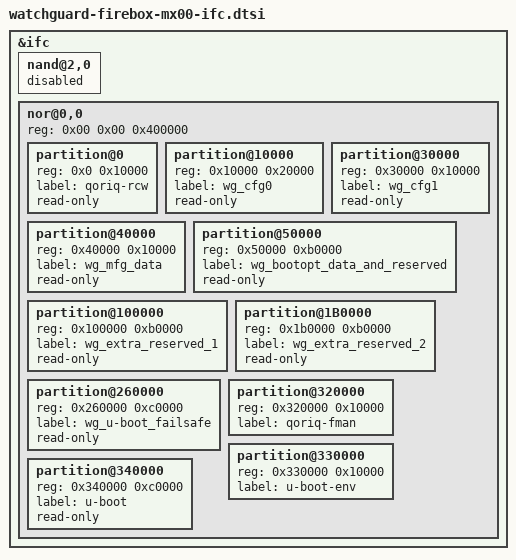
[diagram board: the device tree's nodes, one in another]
&ifc {
	ranges = <0x00 0x00 0x0f 0xefc00000 0x400000>;

	nand@2,0 {
		status = "disabled";
	};

	nor@0,0 {
		reg = <0x00 0x00 0x400000>;

		partition@0{
			reg = <0x0 0x10000>;
			label = "qoriq-rcw";
			read-only;
		};

		partition@10000 {
			reg = <0x10000 0x20000>;
			label = "wg_cfg0";
			read-only;
		};

		partition@30000 {
			reg = <0x30000 0x10000>;
			label = "wg_cfg1";
			read-only;
		};

		partition@40000 {
			reg = <0x40000 0x10000>;
			label = "wg_mfg_data";
			read-only;
		};

		partition@50000 {
			reg = <0x50000 0xb0000>;
			label = "wg_bootopt_data_and_reserved";
			read-only;
		};

		partition@100000 {
			reg = <0x100000 0xb0000>;
			label = "wg_extra_reserved_1";
			read-only;
		};

		partition@1B0000 {
			reg = <0x1b0000 0xb0000>;
			label = "wg_extra_reserved_2";
			read-only;
		};

		partition@260000 {
			reg = <0x260000 0xc0000>;
			label = "wg_u-boot_failsafe";
			read-only;
		};

		partition@320000 {
			reg = <0x320000 0x10000>;
			label = "qoriq-fman";
		};

		partition@330000 {
			reg = <0x330000 0x10000>;
			label = "u-boot-env";
		};

		partition@340000 {
			reg = <0x340000 0xc0000>;
			label = "u-boot";
			read-only;
		};
	};
};
